# RA6M2 register map
Vendor: Renesas Electronics Corporation; Series: RA6; File version: 1.1
CPU: CM4 r0p1, little endian, MPU, FPU, VTOR, 4 interrupt priority bits
Registers are 8-bit, read-write, reset 0x0 unless marked. A register's access mark holds for its fields unless they carry their own. Offsets are from the block's base; [hi:lo] are bit positions; {n}, {i} and the like mark numbered series.

## DAC12 — 12-bit D/A converter
Base 0x4005E000
{0x0+2i} DADR{i} (i=0..1) 16-bit — D/A Data Register {i}
  [15:0] DADR — D/A Data RegisterNOTE: When DADPR.DPSEL = 0, the high-order 4 bits are fixed to 0: right justified format. When DADPR.DPSEL = 1, the low-order 4 bits are fixed to 0: left justified format.
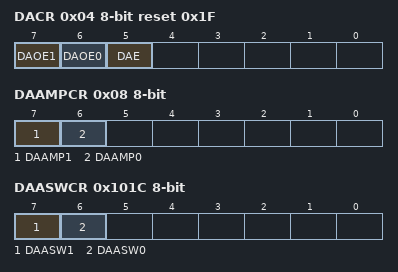
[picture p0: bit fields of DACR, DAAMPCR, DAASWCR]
0x04 DACR reset 0x1F — D/A Control Register
  [7] DAOE1 — D/A Output Enable 1
    0=Analog output of channel 1 (DA1) is disabled; 1=D/A conversion of channel 1 is enabled. Analog output of channel 1 (DA1) is enabled.
  [6] DAOE0 — D/A Output Enable 0
    0=Analog output of channel 0 (DA0) is disabled; 1=D/A conversion of channel 0 is enabled. Analog output of channel 0 (DA0) is enabled.
  [5] DAE — D/A Enable
    0=D/A conversion is independently controlled on channels 0 and 1; 1=D/A conversion on channels 0 and 1 is controlled as a single whole
0x05 DADPR — DADRm Format Select Register
  [7] DPSEL — DADRm Format Select
    0=Right justified format; 1=Left justified format
0x06 DAADSCR — D/A-A/D Synchronous Start Control Register
  [7] DAADST — D/A-A/D Synchronous Conversion
    0=D/A converter operation does not synchronize with A/D converter operation (unit 1) (countermeasure against interference between D/A and A/D conversions is disabled); 1=D/A converter operation synchronizes with A/D converter operation (unit 1) (countermeasure against interference between D/A and A/D conversions is enabled)
0x08 DAAMPCR — D/A Output Amplifier Control Register
  [7] DAAMP1 — Amplifier Control 1
    0=Output amplifier of channel 1 is not used; 1=Output amplifier of channel 1 is used
  [6] DAAMP0 — Amplifier Control 0
    0=Output amplifier of channel 0 is not used; 1=Output amplifier of channel 0 is used
0x101C DAASWCR — D/A Amplifier Stabilization Wait Control Register
  [7] DAASW1 — D/A Amplifier Stabilization Wait 1
    0=Amplifier stabilization wait off (output) for channel 1; 1=Amplifier stabilization wait on (high-Z) for channel 1
  [6] DAASW0 — D/A Amplifier Stabilization Wait 0
    0=Amplifier stabilization wait off (output) for channel 0; 1=Amplifier stabilization wait on (high-Z) for channel 0
0x10C0 DAADUSR — D/A A/D Synchronous Unit Select Register
  [1] AMADSEL1 — A/D Unit 1 Select
    0=Unit 1 is not selected; 1=Unit 1 is selected

## ACMPHS0 — High-Speed Analog Comparator 0
Base 0x40085000
Same registers: ACMPHS1 0x40085100, ACMPHS2 0x40085200, ACMPHS3 0x40085300, ACMPHS4 0x40085400, ACMPHS5 0x40085500
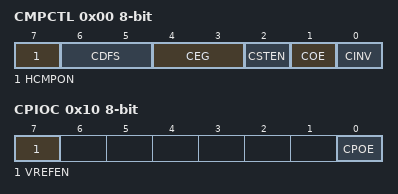
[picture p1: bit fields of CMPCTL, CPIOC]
0x00 CMPCTL — Comparator Control Register
  [7] HCMPON — Comparator operation control
    0=Operation stopped (the comparator outputs a low-level signal); 1=Operation enabled (input to the comparator pins is enabled
  [6:5] CDFS — Noise filter selection
    0=Noise filter not used; 1=Noise filter sampling frequency is 2^3/PCLKB; 2=Noise filter sampling frequency is 2^4/PCLKB; 3=Noise filter sampling frequency is 2^5/PCLKB
  [4:3] CEG — Selection of valid edge (Edge selector)
    0=No edge selection; 1=Rising edge selection; 2=Falling edge selection; 3=Both-edge selection
  [2] CSTEN — Interrupt Select
    0=Output via the Edge selector; 1=Direct output
  [1] COE — Comparator output enable
    0=Comparator output disabled (the output signal is low level); 1=Comparator output enabled
  [0] CINV — Comparator output polarity selection
    0=Comparator output not inverted; 1=Comparator output inverted
0x04 CMPSEL0 — Comparator Input Select Register
  [3:0] CMPSEL — Comparator input selection
    0=No input; 1=IVCMP0 selected; 2=IVCMP1 selected; 4=IVCMP2 selected; 8=IVCMP3 selected; other=others (Setting prohibited)
0x08 CMPSEL1 — Comparator Reference Voltage Select Register
  [3:0] CRVS — Reference voltage selection
    0=No reference voltage; 1=IVREF0 selected; 2=IVREF1 selected; 4=IVREF2 selected; 8=IVREF3 selected; other=others (Setting prohibited)
0x0C CMPMON ro — Comparator Output Monitor Register
  [0] CMPMON — Comparator output monitor
    0=Comparator output Low; 1=Comparator output High
0x10 CPIOC — Comparator Output Control Register
  [7] VREFEN — Internal Vref enable
    0=Internal Vref disable; 1=Internal Vref enable
  [0] CPOE — Comparator output selection
    0=VCOUT pin output of the comparator is disabled (the output signal is low level); 1=VCOUT pin output of the comparator is enabled
